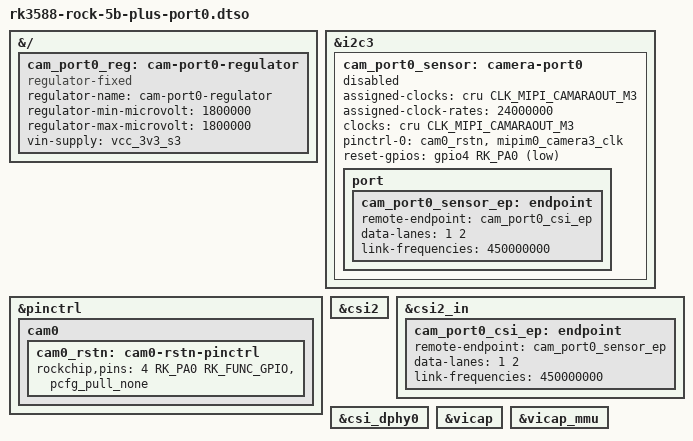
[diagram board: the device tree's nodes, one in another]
// SPDX-License-Identifier: (GPL-2.0+ OR MIT)
/*
 * ROCK 5B+ CAM0 (port0): Inno CSI D-PHY0 + CSI2 on i2c3.
 *
 * Publishes cam_port0_sensor, cam_port0_sensor_ep, cam_port0_csi_ep,
 * and cam_port0_reg. The sensor overlay enables isp0 or isp1. This is
 * the VICAP plus rkisp2 arrangement; it does not wire CSI into the ISP.
 */

/dts-v1/;
/plugin/;

#include <dt-bindings/clock/rockchip,rk3588-cru.h>
#include <dt-bindings/gpio/gpio.h>
#include <dt-bindings/pinctrl/rockchip.h>

&{/} {
	cam_port0_reg: cam-port0-regulator {
		compatible = "regulator-fixed";
		regulator-name = "cam-port0-regulator";
		regulator-min-microvolt = <1800000>;
		regulator-max-microvolt = <1800000>;
		vin-supply = <&vcc_3v3_s3>;
	};
};

&i2c3 {
	#address-cells = <1>;
	#size-cells = <0>;
	status = "okay";

	cam_port0_sensor: camera-port0 {
		status = "disabled";
		assigned-clocks = <&cru CLK_MIPI_CAMARAOUT_M3>;
		assigned-clock-rates = <24000000>;
		clocks = <&cru CLK_MIPI_CAMARAOUT_M3>;
		pinctrl-names = "default";
		pinctrl-0 = <&cam0_rstn &mipim0_camera3_clk>;
		reset-gpios = <&gpio4 RK_PA0 GPIO_ACTIVE_LOW>;

		port {
			cam_port0_sensor_ep: endpoint {
				remote-endpoint = <&cam_port0_csi_ep>;
				data-lanes = <1 2>;
				link-frequencies = /bits/ 64 <450000000>;
			};
		};
	};
};

&pinctrl {
	cam0 {
		cam0_rstn: cam0-rstn-pinctrl {
			rockchip,pins = <4 RK_PA0 RK_FUNC_GPIO &pcfg_pull_none>;
		};
	};
};

&csi2 {
	status = "okay";
};

&csi2_in {
	cam_port0_csi_ep: endpoint {
		remote-endpoint = <&cam_port0_sensor_ep>;
		data-lanes = <1 2>;
		link-frequencies = /bits/ 64 <450000000>;
	};
};

&csi_dphy0 {
	status = "okay";
};

&vicap {
	status = "okay";
};

&vicap_mmu {
	status = "okay";
};
